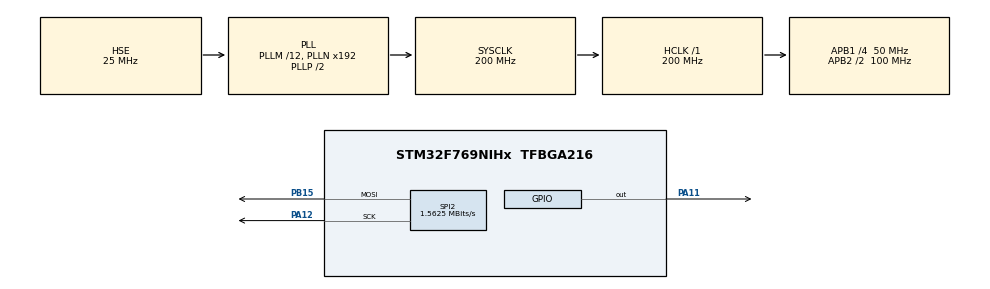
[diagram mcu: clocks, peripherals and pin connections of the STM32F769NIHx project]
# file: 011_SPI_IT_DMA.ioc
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CORTEX_M7.CPU_DCache=Enabled
CORTEX_M7.CPU_ICache=Enabled
CORTEX_M7.DisableExec-Cortex_Memory_Protection_Unit_Region0_Settings=MPU_INSTRUCTION_ACCESS_DISABLE
CORTEX_M7.Enable-Cortex_Memory_Protection_Unit_Region0_Settings=MPU_REGION_ENABLE
CORTEX_M7.IsShareable-Cortex_Memory_Protection_Unit_Region0_Settings=MPU_ACCESS_SHAREABLE
CORTEX_M7.MPU_Control=__NULL
CORTEX_M7.Size-Cortex_Memory_Protection_Unit_Region0_Settings=MPU_REGION_SIZE_4GB
CORTEX_M7.SubRegionDisable-Cortex_Memory_Protection_Unit_Region0_Settings=0x87
CORTEX_M7.default_mode_Activation=0
Dma.Request0=SPI2_TX
Dma.SPI2_TX.0.Direction=DMA_MEMORY_TO_PERIPH
Dma.SPI2_TX.0.FIFOMode=DMA_FIFOMODE_DISABLE
Dma.SPI2_TX.0.Instance=DMA1_Stream4
Dma.SPI2_TX.0.MemDataAlignment=DMA_MDATAALIGN_BYTE
Dma.SPI2_TX.0.MemInc=DMA_MINC_ENABLE
Dma.SPI2_TX.0.Mode=DMA_CIRCULAR
Dma.SPI2_TX.0.PeriphDataAlignment=DMA_PDATAALIGN_BYTE
Dma.SPI2_TX.0.PeriphInc=DMA_PINC_DISABLE
Dma.SPI2_TX.0.Priority=DMA_PRIORITY_LOW
Mcu.Family=STM32F7
Mcu.Name=STM32F769NIHx
Mcu.Package=TFBGA216
NVIC.DMA1_Stream4_IRQn=true\:0\:0\:false\:false\:true\:false\:true\:true
NVIC.PriorityGroup=NVIC_PRIORITYGROUP_4
NVIC.SPI2_IRQn=true\:0\:0\:false\:false\:true\:true\:true\:true
PA11.GPIO_Speed=GPIO_SPEED_FREQ_VERY_HIGH
PA11.PinState=GPIO_PIN_SET
PA11.Signal=GPIO_Output
PA12.Mode=TX_Only_Simplex_Unidirect_Master
PA12.Signal=SPI2_SCK
PA13.Mode=Trace_Asynchronous_SW
PA13.Signal=SYS_JTMS-SWDIO
PA14.Mode=Trace_Asynchronous_SW
PA14.Signal=SYS_JTCK-SWCLK
PB15.Mode=TX_Only_Simplex_Unidirect_Master
PB15.Signal=SPI2_MOSI
PB3.Mode=Trace_Asynchronous_SW
PB3.Signal=SYS_JTDO-SWO
PB9.Signal=SPI2_NSS
PH0/OSC_IN.Mode=HSE-External-Oscillator
PH0/OSC_IN.Signal=RCC_OSC_IN
PH1/OSC_OUT.Mode=HSE-External-Oscillator
PH1/OSC_OUT.Signal=RCC_OSC_OUT
ProjectManager.HeapSize=0x200
ProjectManager.StackSize=0x400
ProjectManager.TargetToolchain=STM32CubeIDE
RCC.AHBFreq_Value=200000000
RCC.APB1CLKDivider=RCC_HCLK_DIV4
RCC.APB1Freq_Value=50000000
RCC.APB1TimFreq_Value=100000000
RCC.APB2CLKDivider=RCC_HCLK_DIV2
RCC.APB2Freq_Value=100000000
RCC.APB2TimFreq_Value=200000000
RCC.CortexFreq_Value=200000000
RCC.HCLKFreq_Value=200000000
RCC.HSE_VALUE=25000000
RCC.HSI_VALUE=16000000
RCC.LSE_VALUE=32768
RCC.PLLM=12
RCC.PLLSourceVirtual=RCC_PLLSOURCE_HSE
RCC.SYSCLKFreq_VALUE=200000000
RCC.SYSCLKSource=RCC_SYSCLKSOURCE_PLLCLK
RCC.USBFreq_Value=200000000
RCC.VCOOutputFreq_Value=400000000
SPI2.BaudRatePrescaler=SPI_BAUDRATEPRESCALER_32
SPI2.CalculateBaudRate=1.5625 MBits/s
SPI2.DataSize=SPI_DATASIZE_8BIT
SPI2.Direction=SPI_DIRECTION_2LINES
SPI2.Mode=SPI_MODE_MASTER
SPI2.NSSPMode=SPI_NSS_PULSE_DISABLE
SPI2.VirtualType=VM_MASTER
board=custom

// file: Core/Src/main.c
/* USER CODE BEGIN Header */
/**
  ******************************************************************************
  * @file           : main.c
  * @brief          : Main program body
  ******************************************************************************
  * @attention
  *
  * Copyright (c) 2023 STMicroelectronics.
  * All rights reserved.
  *
  * This software is licensed under terms that can be found in the LICENSE file
  * in the root directory of this software component.
  * If no LICENSE file comes with this software, it is provided AS-IS.
  *
  ******************************************************************************
  */
/* USER CODE END Header */
#include "main.h"

/* USER CODE BEGIN Includes */
#include "myMain.h"
/* USER CODE END Includes */

SPI_HandleTypeDef hspi2;

void SystemClock_Config(void);
static void MX_GPIO_Init(void);
static void MX_SPI2_Init(void);

int main(void)
{

  /* MCU Configuration--------------------------------------------------------*/

  /* Reset of all peripherals, Initializes the Flash interface and the Systick. */
  HAL_Init();

  /* Configure the system clock */
  SystemClock_Config();

  /* Initialize all configured peripherals */
  MX_GPIO_Init();
  MX_SPI2_Init();

  /* Infinite loop */
  /* USER CODE BEGIN WHILE */
  setup();
  while (1)
  {
	  loop();
    /* USER CODE END WHILE */

  }
}

void SystemClock_Config(void)
{
  RCC_OscInitTypeDef RCC_OscInitStruct = {0};
  RCC_ClkInitTypeDef RCC_ClkInitStruct = {0};

  /** Configure the main internal regulator output voltage
  */
  __HAL_RCC_PWR_CLK_ENABLE();
  __HAL_PWR_VOLTAGESCALING_CONFIG(PWR_REGULATOR_VOLTAGE_SCALE1);

  /** Initializes the RCC Oscillators according to the specified parameters
  * in the RCC_OscInitTypeDef structure.
  */
  RCC_OscInitStruct.OscillatorType = RCC_OSCILLATORTYPE_HSE;
  RCC_OscInitStruct.HSEState = RCC_HSE_ON;
  RCC_OscInitStruct.PLL.PLLState = RCC_PLL_ON;
  RCC_OscInitStruct.PLL.PLLSource = RCC_PLLSOURCE_HSE;
  RCC_OscInitStruct.PLL.PLLM = 12;
  RCC_OscInitStruct.PLL.PLLN = 192;
  RCC_OscInitStruct.PLL.PLLP = RCC_PLLP_DIV2;
  RCC_OscInitStruct.PLL.PLLQ = 2;
  RCC_OscInitStruct.PLL.PLLR = 2;
  if (HAL_RCC_OscConfig(&RCC_OscInitStruct) != HAL_OK)
  {
    Error_Handler();
  }

  /** Activate the Over-Drive mode
  */
  if (HAL_PWREx_EnableOverDrive() != HAL_OK)
  {
    Error_Handler();
  }

  /** Initializes the CPU, AHB and APB buses clocks
  */
  RCC_ClkInitStruct.ClockType = RCC_CLOCKTYPE_HCLK|RCC_CLOCKTYPE_SYSCLK
                              |RCC_CLOCKTYPE_PCLK1|RCC_CLOCKTYPE_PCLK2;
  RCC_ClkInitStruct.SYSCLKSource = RCC_SYSCLKSOURCE_PLLCLK;
  RCC_ClkInitStruct.AHBCLKDivider = RCC_SYSCLK_DIV1;
  RCC_ClkInitStruct.APB1CLKDivider = RCC_HCLK_DIV4;
  RCC_ClkInitStruct.APB2CLKDivider = RCC_HCLK_DIV2;

  if (HAL_RCC_ClockConfig(&RCC_ClkInitStruct, FLASH_LATENCY_6) != HAL_OK)
  {
    Error_Handler();
  }
}

static void MX_SPI2_Init(void)
{

  /* SPI2 parameter configuration*/
  hspi2.Instance = SPI2;
  hspi2.Init.Mode = SPI_MODE_MASTER;
  hspi2.Init.Direction = SPI_DIRECTION_2LINES;
  hspi2.Init.DataSize = SPI_DATASIZE_8BIT;
  hspi2.Init.CLKPolarity = SPI_POLARITY_LOW;
  hspi2.Init.CLKPhase = SPI_PHASE_1EDGE;
  hspi2.Init.NSS = SPI_NSS_HARD_OUTPUT;
  hspi2.Init.BaudRatePrescaler = SPI_BAUDRATEPRESCALER_32;
  hspi2.Init.FirstBit = SPI_FIRSTBIT_MSB;
  hspi2.Init.TIMode = SPI_TIMODE_DISABLE;
  hspi2.Init.CRCCalculation = SPI_CRCCALCULATION_DISABLE;
  hspi2.Init.CRCPolynomial = 7;
  hspi2.Init.CRCLength = SPI_CRC_LENGTH_DATASIZE;
  hspi2.Init.NSSPMode = SPI_NSS_PULSE_ENABLE;
  if (HAL_SPI_Init(&hspi2) != HAL_OK)
  {
    Error_Handler();
  }

}

static void MX_GPIO_Init(void)
{
  GPIO_InitTypeDef GPIO_InitStruct = {0};

  /* GPIO Ports Clock Enable */
  __HAL_RCC_GPIOB_CLK_ENABLE();
  __HAL_RCC_GPIOA_CLK_ENABLE();
  __HAL_RCC_GPIOH_CLK_ENABLE();

  /*Configure GPIO pin Output Level */
  HAL_GPIO_WritePin(GPIOA, GPIO_PIN_11, GPIO_PIN_RESET);

  /*Configure GPIO pin : PA11 */
  GPIO_InitStruct.Pin = GPIO_PIN_11;
  GPIO_InitStruct.Mode = GPIO_MODE_OUTPUT_PP;
  GPIO_InitStruct.Pull = GPIO_NOPULL;
  GPIO_InitStruct.Speed = GPIO_SPEED_FREQ_LOW;
  HAL_GPIO_Init(GPIOA, &GPIO_InitStruct);

}

void Error_Handler(void)
{
  __disable_irq();
  while (1)
  {
  }
}
